VERSION ""

NS_ :

BS_:

BU_: ECU VEHICLE

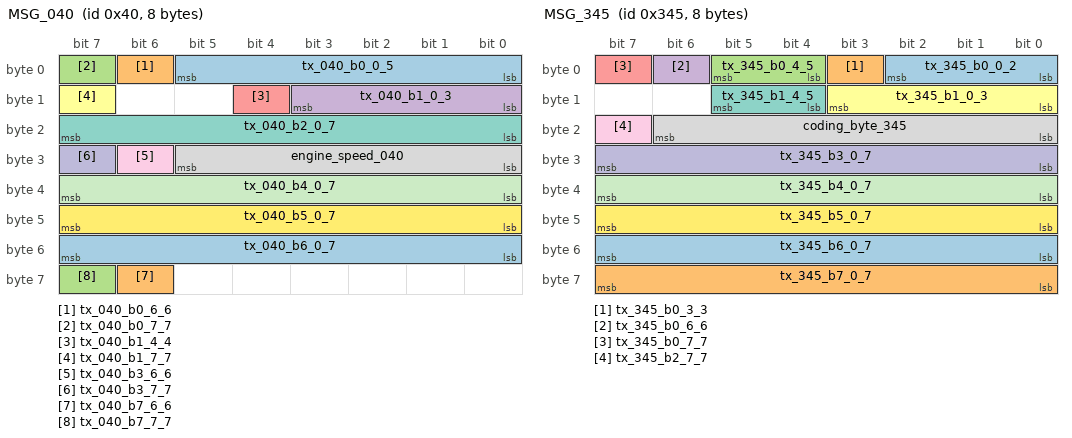
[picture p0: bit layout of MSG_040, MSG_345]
BO_ 64 MSG_040: 8 ECU
 SG_ tx_040_b0_0_5 : 0|6@1+ (1,0) [0|63] "" VEHICLE
 SG_ tx_040_b0_6_6 : 6|1@1+ (1,0) [0|1] "" VEHICLE
 SG_ tx_040_b0_7_7 : 7|1@1+ (1,0) [0|1] "" VEHICLE
 SG_ tx_040_b1_0_3 : 8|4@1+ (1,0) [0|15] "" VEHICLE
 SG_ tx_040_b1_4_4 : 12|1@1+ (1,0) [0|1] "" VEHICLE
 SG_ tx_040_b1_7_7 : 15|1@1+ (1,0) [0|1] "" VEHICLE
 SG_ tx_040_b2_0_7 : 16|8@1+ (1,0) [0|255] "" VEHICLE
 SG_ engine_speed_040 : 24|6@1+ (1,0) [0|63] "" VEHICLE
 SG_ tx_040_b3_6_6 : 30|1@1+ (1,0) [0|1] "" VEHICLE
 SG_ tx_040_b3_7_7 : 31|1@1+ (1,0) [0|1] "" VEHICLE
 SG_ tx_040_b4_0_7 : 32|8@1+ (1,0) [0|255] "" VEHICLE
 SG_ tx_040_b5_0_7 : 40|8@1+ (1,0) [0|255] "" VEHICLE
 SG_ tx_040_b6_0_7 : 48|8@1+ (1,0) [0|255] "" VEHICLE
 SG_ tx_040_b7_6_6 : 62|1@1+ (1,0) [0|1] "" VEHICLE
 SG_ tx_040_b7_7_7 : 63|1@1+ (1,0) [0|1] "" VEHICLE

BO_ 65 MSG_041: 8 ECU
 SG_ tx_041_b0_0_0 : 0|1@1+ (1,0) [0|1] "" VEHICLE
 SG_ tx_041_b0_1_1 : 1|1@1+ (1,0) [0|1] "" VEHICLE
 SG_ tx_041_b0_2_3 : 2|2@1+ (1,0) [0|3] "" VEHICLE
 SG_ tx_041_b0_4_4 : 4|1@1+ (1,0) [0|1] "" VEHICLE
 SG_ tx_041_b0_5_5 : 5|1@1+ (1,0) [0|1] "" VEHICLE
 SG_ tx_041_b0_6_6 : 6|1@1+ (1,0) [0|1] "" VEHICLE
 SG_ tx_041_b0_7_7 : 7|1@1+ (1,0) [0|1] "" VEHICLE
 SG_ tx_041_b1_0_3 : 8|4@1+ (1,0) [0|15] "" VEHICLE
 SG_ tx_041_b2_0_7 : 16|8@1+ (1,0) [0|255] "" VEHICLE
 SG_ tx_041_b3_0_6 : 24|7@1+ (1,0) [0|127] "" VEHICLE
 SG_ tx_041_b3_7_7 : 31|1@1+ (1,0) [0|1] "" VEHICLE
 SG_ tx_041_b4_0_7 : 32|8@1+ (1,0) [0|255] "" VEHICLE
 SG_ tx_041_b5_0_6 : 40|7@1+ (1,0) [0|127] "" VEHICLE
 SG_ tx_041_b5_7_7 : 47|1@1+ (1,0) [0|1] "" VEHICLE
 SG_ tx_041_b6_0_7 : 48|8@1+ (1,0) [0|255] "" VEHICLE
 SG_ tx_041_b7_0_0 : 56|1@1+ (1,0) [0|1] "" VEHICLE
 SG_ tx_041_b7_1_1 : 57|1@1+ (1,0) [0|1] "" VEHICLE
 SG_ tx_041_b7_2_3 : 58|2@1+ (1,0) [0|3] "" VEHICLE
 SG_ tx_041_b7_4_4 : 60|1@1+ (1,0) [0|1] "" VEHICLE
 SG_ tx_041_b7_5_5 : 61|1@1+ (1,0) [0|1] "" VEHICLE

BO_ 72 MSG_048: 8 VEHICLE
 SG_ rx_048_b0_0_7 : 0|8@1+ (1,0) [0|255] "" ECU
 SG_ rx_048_b1_0_3 : 8|4@1+ (1,0) [0|15] "" ECU

BO_ 73 MSG_049: 8 VEHICLE
 SG_ rx_049_b0_0_7 : 0|8@1+ (1,0) [0|255] "" ECU
 SG_ rx_049_b1_0_3 : 8|4@1+ (1,0) [0|15] "" ECU

BO_ 280 MSG_118: 8 VEHICLE
 SG_ rx_118_b0_0_7 : 0|8@1+ (1,0) [0|255] "" ECU
 SG_ rx_118_b1_0_3 : 8|4@1+ (1,0) [0|15] "" ECU

BO_ 313 MSG_139: 8 VEHICLE
 SG_ rx_139_b0_0_7 : 0|8@1+ (1,0) [0|255] "" ECU
 SG_ rx_139_b1_0_3 : 8|4@1+ (1,0) [0|15] "" ECU

BO_ 314 MSG_13A: 8 VEHICLE
 SG_ rx_13a_b0_0_7 : 0|8@1+ (1,0) [0|255] "" ECU
 SG_ rx_13a_b1_0_3 : 8|4@1+ (1,0) [0|15] "" ECU

BO_ 315 MSG_13B: 8 VEHICLE
 SG_ rx_13b_b0_0_7 : 0|8@1+ (1,0) [0|255] "" ECU
 SG_ rx_13b_b1_0_3 : 8|4@1+ (1,0) [0|15] "" ECU

BO_ 326 MSG_146: 8 ECU
 SG_ tx_146_b0_0_1 : 0|2@1+ (1,0) [0|3] "" VEHICLE
 SG_ tx_146_b0_2_2 : 2|1@1+ (1,0) [0|1] "" VEHICLE
 SG_ tx_146_b0_3_5 : 3|3@1+ (1,0) [0|7] "" VEHICLE
 SG_ tx_146_b0_6_6 : 6|1@1+ (1,0) [0|1] "" VEHICLE
 SG_ tx_146_b0_7_7 : 7|1@1+ (1,0) [0|1] "" VEHICLE
 SG_ tx_146_b1_0_3 : 8|4@1+ (1,0) [0|15] "" VEHICLE
 SG_ tx_146_b1_4_6 : 12|3@1+ (1,0) [0|7] "" VEHICLE
 SG_ tx_146_b1_7_7 : 15|1@1+ (1,0) [0|1] "" VEHICLE
 SG_ tx_146_b2_0_7 : 16|8@1+ (1,0) [0|255] "" VEHICLE
 SG_ engine_speed_filtered_146 : 24|6@1+ (1,0) [0|63] "" VEHICLE
 SG_ tx_146_b3_6_6 : 30|1@1+ (1,0) [0|1] "" VEHICLE
 SG_ tx_146_b3_7_7 : 31|1@1+ (1,0) [0|1] "" VEHICLE
 SG_ tx_146_b4_0_7 : 32|8@1+ (1,0) [0|255] "" VEHICLE
 SG_ tx_146_b5_0_0 : 40|1@1+ (1,0) [0|1] "" VEHICLE
 SG_ tx_146_b5_1_1 : 41|1@1+ (1,0) [0|1] "" VEHICLE
 SG_ tx_146_b5_2_2 : 42|1@1+ (1,0) [0|1] "" VEHICLE
 SG_ tx_146_b5_3_5 : 43|3@1+ (1,0) [0|7] "" VEHICLE
 SG_ tx_146_b5_6_6 : 46|1@1+ (1,0) [0|1] "" VEHICLE

BO_ 372 MSG_174: 8 VEHICLE

BO_ 545 MSG_221: 8 VEHICLE
 SG_ rx_221_b0_0_7 : 0|8@1+ (1,0) [0|255] "" ECU
 SG_ rx_221_b1_0_3 : 8|4@1+ (1,0) [0|15] "" ECU

BO_ 576 MSG_240: 8 ECU
 SG_ tx_240_b0_0_0 : 0|1@1+ (1,0) [0|1] "" VEHICLE
 SG_ tx_240_b0_1_1 : 1|1@1+ (1,0) [0|1] "" VEHICLE
 SG_ tx_240_b0_2_2 : 2|1@1+ (1,0) [0|1] "" VEHICLE
 SG_ tx_240_b0_3_5 : 3|3@1+ (1,0) [0|7] "" VEHICLE
 SG_ tx_240_b0_6_6 : 6|1@1+ (1,0) [0|1] "" VEHICLE
 SG_ tx_240_b0_7_7 : 7|1@1+ (1,0) [0|1] "" VEHICLE
 SG_ tx_240_b1_0_3 : 8|4@1+ (1,0) [0|15] "" VEHICLE
 SG_ tx_240_b3_0_0 : 24|1@1+ (1,0) [0|1] "" VEHICLE
 SG_ tx_240_b3_1_1 : 25|1@1+ (1,0) [0|1] "" VEHICLE
 SG_ tx_240_b3_2_2 : 26|1@1+ (1,0) [0|1] "" VEHICLE
 SG_ tx_240_b3_3_3 : 27|1@1+ (1,0) [0|1] "" VEHICLE
 SG_ tx_240_b3_4_4 : 28|1@1+ (1,0) [0|1] "" VEHICLE
 SG_ tx_240_b3_5_6 : 29|2@1+ (1,0) [0|3] "" VEHICLE
 SG_ tx_240_b3_7_7 : 31|1@1+ (1,0) [0|1] "" VEHICLE
 SG_ tx_240_b4_0_2 : 32|3@1+ (1,0) [0|7] "" VEHICLE
 SG_ tx_240_b4_3_5 : 35|3@1+ (1,0) [0|7] "" VEHICLE
 SG_ tx_240_b4_6_7 : 38|2@1+ (1,0) [0|3] "" VEHICLE
 SG_ tx_240_b5_0_2 : 40|3@1+ (1,0) [0|7] "" VEHICLE
 SG_ tx_240_b5_3_3 : 43|1@1+ (1,0) [0|1] "" VEHICLE
 SG_ tx_240_b5_4_5 : 44|2@1+ (1,0) [0|3] "" VEHICLE
 SG_ tx_240_b5_6_6 : 46|1@1+ (1,0) [0|1] "" VEHICLE
 SG_ tx_240_b5_7_7 : 47|1@1+ (1,0) [0|1] "" VEHICLE
 SG_ tx_240_b6_0_2 : 48|3@1+ (1,0) [0|7] "" VEHICLE
 SG_ tx_240_b6_3_3 : 51|1@1+ (1,0) [0|1] "" VEHICLE
 SG_ tx_240_b6_6_6 : 54|1@1+ (1,0) [0|1] "" VEHICLE
 SG_ tx_240_b7_5_5 : 61|1@1+ (1,0) [0|1] "" VEHICLE

BO_ 577 MSG_241: 8 ECU
 SG_ tx_241_b0_0_1 : 0|2@1+ (1,0) [0|3] "" VEHICLE
 SG_ tx_241_b0_2_2 : 2|1@1+ (1,0) [0|1] "" VEHICLE
 SG_ tx_241_b0_3_4 : 3|2@1+ (1,0) [0|3] "" VEHICLE
 SG_ tx_241_b0_5_5 : 5|1@1+ (1,0) [0|1] "" VEHICLE
 SG_ tx_241_b0_6_7 : 6|2@1+ (1,0) [0|3] "" VEHICLE
 SG_ tx_241_b1_0_3 : 8|4@1+ (1,0) [0|15] "" VEHICLE
 SG_ tx_241_b2_0_7 : 16|8@1+ (1,0) [0|255] "" VEHICLE
 SG_ tx_241_b3_0_7 : 24|8@1+ (1,0) [0|255] "" VEHICLE
 SG_ tx_241_b4_3_5 : 35|3@1+ (1,0) [0|7] "" VEHICLE
 SG_ tx_241_b4_6_7 : 38|2@1+ (1,0) [0|3] "" VEHICLE
 SG_ tx_241_b5_0_0 : 40|1@1+ (1,0) [0|1] "" VEHICLE
 SG_ tx_241_b5_1_1 : 41|1@1+ (1,0) [0|1] "" VEHICLE
 SG_ tx_241_b5_5_5 : 45|1@1+ (1,0) [0|1] "" VEHICLE
 SG_ tx_241_b5_6_6 : 46|1@1+ (1,0) [0|1] "" VEHICLE
 SG_ tx_241_b6_0_4 : 48|5@1+ (1,0) [0|31] "" VEHICLE
 SG_ tx_241_b6_6_7 : 54|2@1+ (1,0) [0|3] "" VEHICLE
 SG_ tx_241_b7_0_7 : 56|8@1+ (1,0) [0|255] "" VEHICLE

BO_ 722 MSG_2D2: 8 VEHICLE
 SG_ rx_2d2_b0_0_7 : 0|8@1+ (1,0) [0|255] "" ECU
 SG_ rx_2d2_b1_0_3 : 8|4@1+ (1,0) [0|15] "" ECU

BO_ 826 MSG_33A: 8 VEHICLE
 SG_ rx_33a_b0_0_7 : 0|8@1+ (1,0) [0|255] "" ECU
 SG_ rx_33a_b1_0_3 : 8|4@1+ (1,0) [0|15] "" ECU

BO_ 837 MSG_345: 8 ECU
 SG_ tx_345_b0_0_2 : 0|3@1+ (1,0) [0|7] "" VEHICLE
 SG_ tx_345_b0_3_3 : 3|1@1+ (1,0) [0|1] "" VEHICLE
 SG_ tx_345_b0_4_5 : 4|2@1+ (1,0) [0|3] "" VEHICLE
 SG_ tx_345_b0_6_6 : 6|1@1+ (1,0) [0|1] "" VEHICLE
 SG_ tx_345_b0_7_7 : 7|1@1+ (1,0) [0|1] "" VEHICLE
 SG_ tx_345_b1_0_3 : 8|4@1+ (1,0) [0|15] "" VEHICLE
 SG_ tx_345_b1_4_5 : 12|2@1+ (1,0) [0|3] "" VEHICLE
 SG_ coding_byte_345 : 16|7@1+ (1,0) [0|127] "" VEHICLE
 SG_ tx_345_b2_7_7 : 23|1@1+ (1,0) [0|1] "" VEHICLE
 SG_ tx_345_b3_0_7 : 24|8@1+ (1,0) [0|255] "" VEHICLE
 SG_ tx_345_b4_0_7 : 32|8@1+ (1,0) [0|255] "" VEHICLE
 SG_ tx_345_b5_0_7 : 40|8@1+ (1,0) [0|255] "" VEHICLE
 SG_ tx_345_b6_0_7 : 48|8@1+ (1,0) [0|255] "" VEHICLE
 SG_ tx_345_b7_0_7 : 56|8@1+ (1,0) [0|255] "" VEHICLE

BO_ 838 MSG_346: 8 ECU
 SG_ tx_346_b0_0_0 : 0|1@1+ (1,0) [0|1] "" VEHICLE
 SG_ tx_346_b0_1_2 : 1|2@1+ (1,0) [0|3] "" VEHICLE
 SG_ tx_346_b0_3_3 : 3|1@1+ (1,0) [0|1] "" VEHICLE
 SG_ tx_346_b0_4_4 : 4|1@1+ (1,0) [0|1] "" VEHICLE
 SG_ tx_346_b0_5_5 : 5|1@1+ (1,0) [0|1] "" VEHICLE
 SG_ tx_346_b0_6_6 : 6|1@1+ (1,0) [0|1] "" VEHICLE
 SG_ tx_346_b0_7_7 : 7|1@1+ (1,0) [0|1] "" VEHICLE
 SG_ tx_346_b1_0_3 : 8|4@1+ (1,0) [0|15] "" VEHICLE
 SG_ tx_346_b1_4_4 : 12|1@1+ (1,0) [0|1] "" VEHICLE
 SG_ tx_346_b1_5_5 : 13|1@1+ (1,0) [0|1] "" VEHICLE
 SG_ tx_346_b1_6_6 : 14|1@1+ (1,0) [0|1] "" VEHICLE
 SG_ tx_346_b1_7_7 : 15|1@1+ (1,0) [0|1] "" VEHICLE
 SG_ tx_346_b2_0_7 : 16|8@1+ (1,0) [0|255] "" VEHICLE
 SG_ tx_346_b3_0_7 : 24|8@1+ (1,0) [0|255] "" VEHICLE
 SG_ tx_346_b4_0_7 : 32|8@1+ (1,0) [0|255] "" VEHICLE
 SG_ tx_346_b5_0_7 : 40|8@1+ (1,0) [0|255] "" VEHICLE
 SG_ tx_346_b6_0_7 : 48|8@1+ (1,0) [0|255] "" VEHICLE
 SG_ tx_346_b7_0_7 : 56|8@1+ (1,0) [0|255] "" VEHICLE

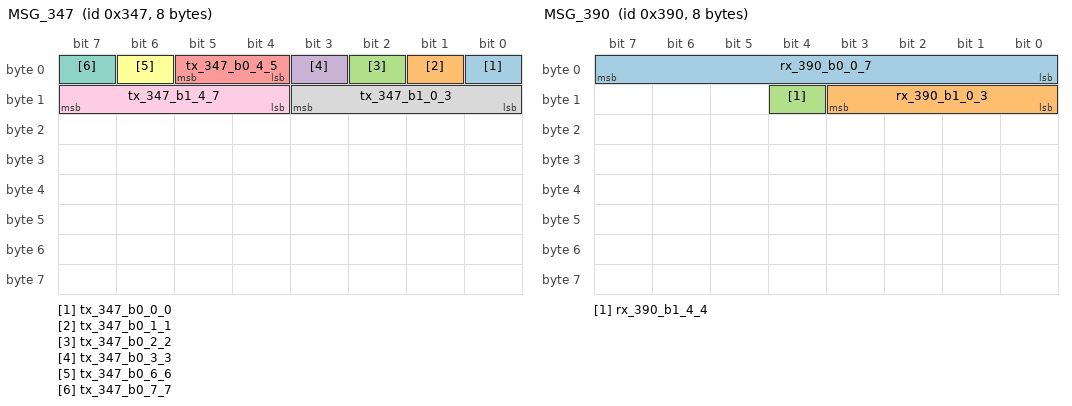
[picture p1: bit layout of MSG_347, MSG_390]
BO_ 839 MSG_347: 8 ECU
 SG_ tx_347_b0_0_0 : 0|1@1+ (1,0) [0|1] "" VEHICLE
 SG_ tx_347_b0_1_1 : 1|1@1+ (1,0) [0|1] "" VEHICLE
 SG_ tx_347_b0_2_2 : 2|1@1+ (1,0) [0|1] "" VEHICLE
 SG_ tx_347_b0_3_3 : 3|1@1+ (1,0) [0|1] "" VEHICLE
 SG_ tx_347_b0_4_5 : 4|2@1+ (1,0) [0|3] "" VEHICLE
 SG_ tx_347_b0_6_6 : 6|1@1+ (1,0) [0|1] "" VEHICLE
 SG_ tx_347_b0_7_7 : 7|1@1+ (1,0) [0|1] "" VEHICLE
 SG_ tx_347_b1_0_3 : 8|4@1+ (1,0) [0|15] "" VEHICLE
 SG_ tx_347_b1_4_7 : 12|4@1+ (1,0) [0|15] "" VEHICLE

BO_ 842 MSG_34A: 8 VEHICLE
 SG_ rx_34a_b0_0_7 : 0|8@1+ (1,0) [0|255] "" ECU
 SG_ rx_34a_b1_0_3 : 8|4@1+ (1,0) [0|15] "" ECU

BO_ 912 MSG_390: 8 VEHICLE
 SG_ rx_390_b0_0_7 : 0|8@1+ (1,0) [0|255] "" ECU
 SG_ rx_390_b1_0_3 : 8|4@1+ (1,0) [0|15] "" ECU
 SG_ rx_390_b1_4_4 : 12|1@1+ (1,0) [0|1] "" ECU

BO_ 915 MSG_393: 8 VEHICLE
 SG_ rx_393_b0_0_7 : 0|8@1+ (1,0) [0|255] "" ECU
 SG_ rx_393_b1_0_3 : 8|4@1+ (1,0) [0|15] "" ECU

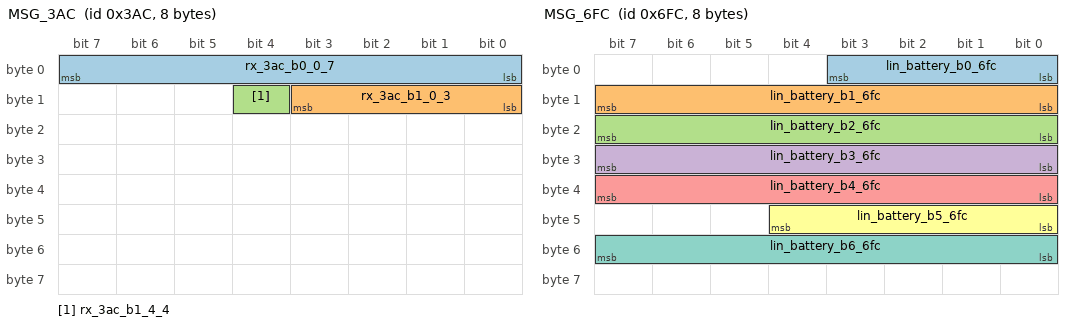
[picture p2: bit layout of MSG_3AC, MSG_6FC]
BO_ 940 MSG_3AC: 8 VEHICLE
 SG_ rx_3ac_b0_0_7 : 0|8@1+ (1,0) [0|255] "" ECU
 SG_ rx_3ac_b1_0_3 : 8|4@1+ (1,0) [0|15] "" ECU
 SG_ rx_3ac_b1_4_4 : 12|1@1+ (1,0) [0|1] "" ECU

BO_ 1632 MSG_660: 8 VEHICLE

BO_ 1677 MSG_68D: 8 VEHICLE
 SG_ rx_68d_b0_0_7 : 0|8@1+ (1,0) [0|255] "" ECU
 SG_ rx_68d_b1_0_3 : 8|4@1+ (1,0) [0|15] "" ECU

BO_ 1788 MSG_6FC: 8 ECU
 SG_ lin_battery_b0_6fc : 0|4@1+ (1,0) [0|15] "" VEHICLE
 SG_ lin_battery_b1_6fc : 8|8@1+ (1,0) [0|255] "" VEHICLE
 SG_ lin_battery_b2_6fc : 16|8@1+ (1,0) [0|255] "" VEHICLE
 SG_ lin_battery_b3_6fc : 24|8@1+ (1,0) [0|255] "" VEHICLE
 SG_ lin_battery_b4_6fc : 32|8@1+ (1,0) [0|255] "" VEHICLE
 SG_ lin_battery_b5_6fc : 40|5@1+ (1,0) [0|31] "" VEHICLE
 SG_ lin_battery_b6_6fc : 48|8@1+ (1,0) [0|255] "" VEHICLE

BO_ 1905 MSG_771: 8 ECU

BO_ 1906 MSG_772: 8 ECU

BO_ 1907 MSG_773: 8 ECU

BO_ 1908 MSG_774: 8 ECU

BO_ 1909 MSG_775: 8 ECU

BO_ 2015 MSG_7DF: 8 VEHICLE

BO_ 2016 MSG_7E0: 8 VEHICLE

BO_ 2024 MSG_7E8: 8 ECU
